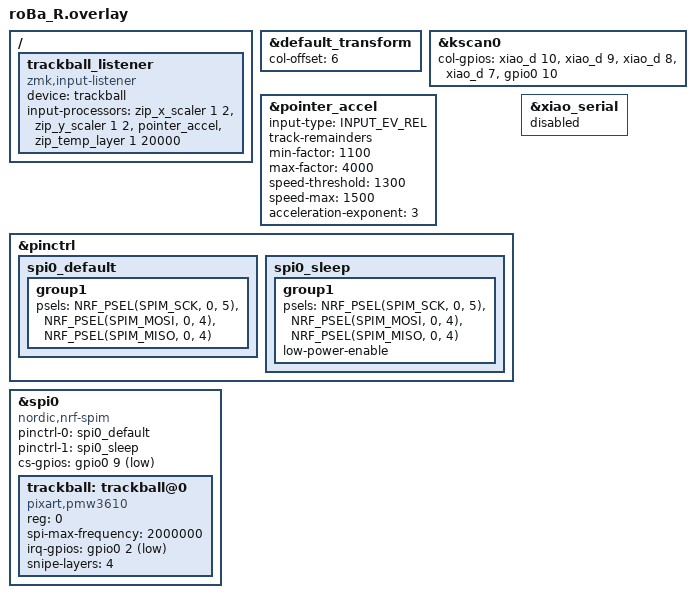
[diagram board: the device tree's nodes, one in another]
#include "roBa.dtsi"
#include <zephyr/dt-bindings/input/input-event-codes.h>
#include <behaviors/input_gestures_accel.dtsi>

&default_transform {
    col-offset = <6>;
};

&kscan0 {
        col-gpios
            = <&xiao_d 10 GPIO_ACTIVE_HIGH>
            , <&xiao_d 9 GPIO_ACTIVE_HIGH>
            , <&xiao_d 8 GPIO_ACTIVE_HIGH>
            , <&xiao_d 7 GPIO_ACTIVE_HIGH>
            , <&gpio0 10 GPIO_ACTIVE_HIGH>
            ;
};

/* トラックボールのポインタ加速。カーソルを速く動かすほど移動量が
   大きくなる。値は千分率(1000=等倍)。 */

&pointer_accel {
    input-type = <INPUT_EV_REL>;
    track-remainders;            // 端数を蓄積して精度低下を防ぐ

    min-factor = <1100>;         // ゆっくり動かした時の倍率
    max-factor = <4000>;         // 速く動かした時は最大4倍まで加速
    speed-threshold = <1300>;    // これ未満の速度では min-factor
    speed-max = <1500>;          // これ以上の速度で最大倍率に到達
    acceleration-exponent = <3>; // 1=線形 / 2=二次関数的 / 3=三次関数的カーブ
};

/ {
    trackball_listener {
        status = "okay";
        compatible = "zmk,input-listener";
        device = <&trackball>;

        /* スケーラー → 加速 → オートマウス(MOUSEレイヤー1, 20秒で解除) */
        input-processors = <
            &zip_x_scaler 1 2
            &zip_y_scaler 1 2
            &pointer_accel
            &zip_temp_layer 1 20000
        >;
    };
};

&pinctrl {
    spi0_default: spi0_default {
        group1 {
            psels = <NRF_PSEL(SPIM_SCK, 0, 5)>,
                <NRF_PSEL(SPIM_MOSI, 0, 4)>,
                <NRF_PSEL(SPIM_MISO, 0, 4)>;
        };
    };

    spi0_sleep: spi0_sleep {
        group1 {
            psels = <NRF_PSEL(SPIM_SCK, 0, 5)>,
                <NRF_PSEL(SPIM_MOSI, 0, 4)>,
                <NRF_PSEL(SPIM_MISO, 0, 4)>;
            low-power-enable;
        };
    };
};

&xiao_serial { status = "disabled"; };

&spi0 {
    status = "okay";
    compatible = "nordic,nrf-spim";
    pinctrl-0 = <&spi0_default>;
    pinctrl-1 = <&spi0_sleep>;
    pinctrl-names = "default", "sleep";
    cs-gpios = <&gpio0 9 GPIO_ACTIVE_LOW>;

    trackball: trackball@0 {
        status = "okay";
        compatible = "pixart,pmw3610";
        reg = <0>;
        spi-max-frequency = <2000000>;
        irq-gpios = <&gpio0 2 (GPIO_ACTIVE_LOW | GPIO_PULL_UP)>;
        snipe-layers = <4>;
    };
};
